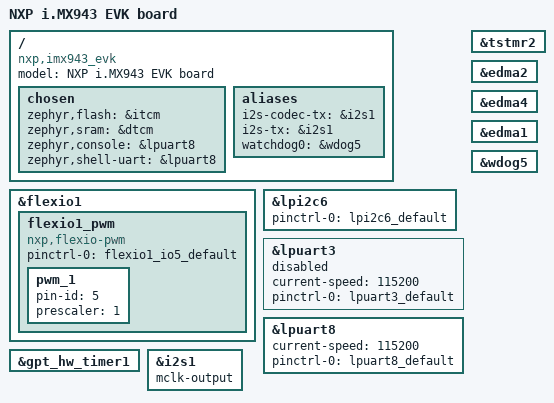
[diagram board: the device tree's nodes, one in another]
/*
 * SPDX-FileCopyrightText: Copyright 2025-2026 NXP
 * SPDX-License-Identifier: Apache-2.0
 */

/dts-v1/;

#include <nxp/imx/nxp_imx943_m33.dtsi>
#include "imx943_evk-pinctrl.dtsi"
#include "imx943_evk_mimx94398_cm.dtsi"

/ {
	compatible = "nxp,imx943_evk";
	model = "NXP i.MX943 EVK board";

	chosen {
		zephyr,flash = &itcm;
		zephyr,sram = &dtcm;

		zephyr,console = &lpuart8;
		zephyr,shell-uart = &lpuart8;
	};

	aliases {
		i2s-codec-tx = &i2s1;
		i2s-tx = &i2s1;
		watchdog0 = &wdog5;
	};
};

&flexio1 {
	status = "okay";

	/* Signal can be checked by the connector J44 Pin10(M1_LED_TP1) via logic analyzer */
	flexio1_pwm: flexio1_pwm {
		compatible = "nxp,flexio-pwm";
		#pwm-cells = <3>;
		pinctrl-0 = <&flexio1_io5_default>;
		pinctrl-names = "default";

		status = "okay";

		pwm_1 {
			pin-id = <5>;
			prescaler = <1>;
		};
	};
};

&lpi2c6 {
	pinctrl-0 = <&lpi2c6_default>;
	pinctrl-names = "default";
	status = "okay";
};

&lpuart3 {
	current-speed = <115200>;
	pinctrl-0 = <&lpuart3_default>;
	pinctrl-names = "default";
	status = "disabled";
};

&lpuart8 {
	current-speed = <115200>;
	pinctrl-0 = <&lpuart8_default>;
	pinctrl-names = "default";
	status = "okay";
};

&gpt_hw_timer1 {
	status = "okay";
};

&tstmr2 {
	status = "okay";
};

&edma2 {
	status = "okay";
};

&edma4 {
	status = "okay";
};

&i2s1 {
	mclk-output;
	status = "okay";
};

&edma1 {
	status = "okay";
};

&wdog5 {
	status = "okay";
};
